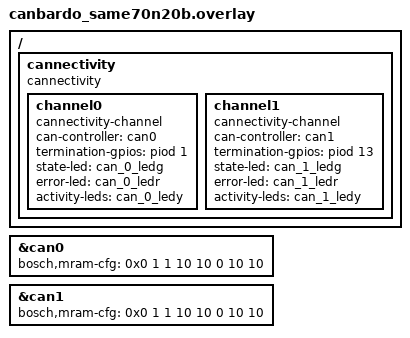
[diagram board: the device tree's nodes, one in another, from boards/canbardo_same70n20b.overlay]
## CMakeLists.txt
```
# Copyright (c) 2024 Henrik Brix Andersen <henrik@brixandersen.dk>
# SPDX-License-Identifier: Apache-2.0

cmake_minimum_required(VERSION 3.13.1)
find_package(Zephyr REQUIRED HINTS $ENV{ZEPHYR_BASE})

project(cannectivity LANGUAGES C)

if(CONFIG_CANNECTIVITY_USB_VID EQUAL 0x1209)
  if(CONFIG_CANNECTIVITY_USB_PID LESS_EQUAL 0x0010)
    message(WARNING
      "CONFIG_CANNECTIVITY_USB_PID is set to a generic pid.codes Test PID (${CONFIG_CANNECTIVITY_USB_PID}).
This PID is not unique and should not be used outside test environments."
      )
  endif()
endif()

if(CONFIG_CANNECTIVITY_DFU_BACKEND_APP)
  if(CONFIG_CANNECTIVITY_USB_DFU_VID EQUAL 0x1209)
    if(CONFIG_CANNECTIVITY_USB_DFU_PID LESS_EQUAL 0x0010)
      message(WARNING
        "CONFIG_CANNECTIVITY_USB_DFU_PID is set to a generic pid.codes Test PID (${CONFIG_CANNECTIVITY_USB_DFU_PID}).
This PID is not unique and should not be used outside test environments."
        )
    endif()
  endif()
endif()

target_sources(app PRIVATE
  src/main.c
  src/usb.c
)

target_sources_ifdef(CONFIG_CANNECTIVITY_LED app PRIVATE
  src/led.c
)

target_sources_ifdef(CONFIG_CANNECTIVITY_TIMESTAMP_COUNTER app PRIVATE
  src/timestamp-counter.c
)

target_sources_ifdef(CONFIG_CANNECTIVITY_TIMESTAMP_UPTIME app PRIVATE
  src/timestamp-uptime.c
)

target_sources_ifdef(CONFIG_CANNECTIVITY_TERMINATION_GPIO app PRIVATE
  src/termination.c
)

target_sources_ifdef(CONFIG_CANNECTIVITY_DFU_SUPPORT app PRIVATE
  src/dfu.c
)
```

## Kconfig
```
# Copyright (c) 2024-2025 Henrik Brix Andersen <henrik@brixandersen.dk>
# SPDX-License-Identifier: Apache-2.0

menu "CANnectivity"

module = CANNECTIVITY
module-str = CANnectivity
source "subsys/logging/Kconfig.template.log_config"

configdefault CAN_FD_MODE
	default y

config CANNECTIVITY_BOOT_BANNER
	bool "CANnectivity boot banner"
	default y if BOOT_BANNER
	select PRINTK
	help
	  Print the CANnectivity firmware version during boot up.

config CANNECTIVITY_USB_MANUFACTURER
	string "USB device manufacturer string"
	default "CANnectivity"
	help
	  CANnectivity USB device manufacturer string.

config CANNECTIVITY_USB_PRODUCT
	string "USB device product string"
	default "CANnectivity USB to CAN adapter"
	help
	  CANnectivity USB device product string.

config CANNECTIVITY_USB_VID
	hex "USB device Vendor ID (VID)"
	default 0x1209
	help
	  CANnectivity USB device Vendor ID (VID).

config CANNECTIVITY_USB_PID
	hex "USB device Product ID (PID)"
	default 0xca01
	help
	  CANnectivity USB device Product ID (PID).

config CANNECTIVITY_USB_SELF_POWERED
	bool "USB device is self-powered"
	default y
	help
	  CANnectivity USB device is self-powered.

config CANNECTIVITY_USB_MAX_POWER
	int "USB device maximum power"
	default 125
	range 0 250
	help
	  CANnectivity USB maximum current draw in milliampere (mA) divided by 2.
	  A value of 125 results in a maximum current draw value of 250 mA.

config CANNECTIVITY_MAX_CHANNELS
	int "Maximum number of supported channels"
	default 1 if !$(dt_compat_enabled,cannectivity-channel)
	default $(dt_compat_enabled_num,cannectivity-channel) if $(dt_compat_enabled,cannectivity-channel)
	range 1 256
	help
	  Maximum number of supported Geschwister Schneider USB/CAN (gs_usb) channels. Each channel
	  represents one CAN controller.

	  The Linux kernel driver supports up to 3 channels. Other drivers may support just one
	  channel.

if USB_DEVICE_STACK

configdefault USB_DEVICE_MANUFACTURER
	default CANNECTIVITY_USB_MANUFACTURER

configdefault USB_DEVICE_PRODUCT
	default CANNECTIVITY_USB_PRODUCT

configdefault USB_DEVICE_VID
	default CANNECTIVITY_USB_VID

configdefault USB_DEVICE_PID
	default CANNECTIVITY_USB_PID

configdefault USB_SELF_POWERED
	default CANNECTIVITY_USB_SELF_POWERED

configdefault USB_MAX_POWER
	default CANNECTIVITY_USB_MAX_POWER

configdefault USB_DEVICE_GS_USB_MAX_CHANNELS
	default CANNECTIVITY_MAX_CHANNELS

configdefault USB_DEVICE_BOS
	default y

configdefault USB_DEVICE_INITIALIZE_AT_BOOT
	default n

endif # USB_DEVICE_STACK

if USB_DEVICE_STACK_NEXT

configdefault USBD_GS_USB_MAX_CHANNELS
	default CANNECTIVITY_MAX_CHANNELS

endif # USB_DEVICE_STACK_NEXT

config CANNECTIVITY_LED
	bool "LED support"
	default y
	depends on $(dt_compat_any_has_prop,cannectivity-channel,state-led) || \
		   $(dt_compat_any_has_prop,cannectivity-channel,activity-leds) || \
		   ($(dt_alias_enabled,led0) && !$(dt_compat_enabled,cannectivity))
	select LED
	select SMF
	select SMF_ANCESTOR_SUPPORT
	select SMF_INITIAL_TRANSITION
	select POLL
	select USB_DEVICE_GS_USB_IDENTIFICATION if USB_DEVICE_GS_USB
	select USBD_GS_USB_IDENTIFICATION if USBD_GS_USB
	help
	  Enable support for CAN channel status/activity LEDs.

if CANNECTIVITY_LED

config CANNECTIVITY_LED_EVENT_MSGQ_SIZE
	int "LED event message queue size"
	default 10
	help
	  Number of per-channel LED events that can be queued for the finite-state machine.

endif # CANNECTIVITY_LED

config CANNECTIVITY_TIMESTAMP
	bool # hidden
	select USB_DEVICE_GS_USB_TIMESTAMP if USB_DEVICE_GS_USB
	select USBD_GS_USB_TIMESTAMP if USBD_GS_USB
	help
	  Enable support for hardware timestamps.

config CANNECTIVITY_TIMESTAMP_COUNTER
	bool "Hardware timestamp support (32-bit counter @ 1MHz)"
	default y
	depends on $(dt_nodelabel_has_prop,cannectivity,timestamp-counter)
	select COUNTER
	select CANNECTIVITY_TIMESTAMP
	help
	  Enable support for hardware timestamps. This requires a 32-bit counter instance running @
	  1MHz.

config CANNECTIVITY_TIMESTAMP_UPTIME
	bool "Hardware timestamp support (64-bit cycle counter)"
	default y
	depends on TIMER_HAS_64BIT_CYCLE_COUNTER
	depends on !CANNECTIVITY_TIMESTAMP_COUNTER
	select CANNECTIVITY_TIMESTAMP
	help
	  Enable support for hardware timestamps. This requires a 64-bit cycle counter.

config CANNECTIVITY_TERMINATION_GPIO
	bool "CAN bus termination resistor support"
	default y
	depends on $(dt_compat_any_has_prop,cannectivity-channel,termination-gpios)
	select USB_DEVICE_GS_USB_TERMINATION if USB_DEVICE_GS_USB
	select USBD_GS_USB_TERMINATION if USBD_GS_USB
	select GPIO
	help
	  Enable support for GPIO-controlled CAN bus termination resistors.

config CANNECTIVITY_TERMINATION_DEFAULT_ON
	bool "Enable CAN bus termination resistors on boot-up"
	default y
	depends on CANNECTIVITY_TERMINATION_GPIO
	help
	  Enable CAN bus termination resistors on boot-up.

menuconfig CANNECTIVITY_DFU_SUPPORT
	bool "Device Firmware Upgrade (DFU) support"
	default y if BOOTLOADER_MCUBOOT
	help
	  Enable Device Firmware Upgrade (DFU) support.

if CANNECTIVITY_DFU_SUPPORT

choice CANNECTIVITY_DFU_BACKEND
	bool "DFU backend"
	default CANNECTIVITY_DFU_BACKEND_NONE if !BOOTLOADER_MCUBOOT
	default CANNECTIVITY_DFU_BACKEND_MCUBOOT if BOOTLOADER_MCUBOOT && USB_DEVICE_STACK
	default CANNECTIVITY_DFU_BACKEND_MCUBOOT if BOOTLOADER_MCUBOOT && MCUBOOT_BOOTLOADER_MODE_SINGLE_APP
	default CANNECTIVITY_DFU_BACKEND_APP if BOOTLOADER_MCUBOOT && USB_DEVICE_STACK_NEXT

config CANNECTIVITY_DFU_BACKEND_NONE
	bool "No backend"
	help
	  Device Firmware Upgrade is handled by an on-chip ROM bootloader.

config CANNECTIVITY_DFU_BACKEND_MCUBOOT
	bool "MCUboot"
	depends on BOOTLOADER_MCUBOOT
	help
	  Device Firmware Upgrade is handled by rebooting into MCUboot, with the bootloader exposing
	  an USB DFU or serial recovery interface.

config CANNECTIVITY_DFU_BACKEND_APP
	bool "Application"
	depends on BOOTLOADER_MCUBOOT && !MCUBOOT_BOOTLOADER_MODE_SINGLE_APP && USB_DEVICE_STACK_NEXT
	help
	  Device Firmware Upgrade is handled by the CANnectivity firmware application. The upgrade
	  process is handled by MCUboot upon reboot.

endchoice

config CANNECTIVITY_DFU_REBOOT
	bool "Automatic reboot upon DFU download completion"
	depends on CANNECTIVITY_DFU_BACKEND_APP
	default y
	select REBOOT
	help
	  Automatically reboot device upon completion of a DFU download.

config CANNECTIVITY_DFU_REBOOT_DELAY
	int "Reboot delay"
	default 100
	range 0 60000
	depends on CANNECTIVITY_DFU_REBOOT
	help
	  Delay in milliseconds between completion of a DFU download and device reboot.

config CANNECTIVITY_USB_DFU_PRODUCT
	string "USB DFU device product string"
	default "CANnectivity USB to CAN adapter (DFU)"
	depends on CANNECTIVITY_DFU_BACKEND_APP
	help
	  CANnectivity USB device DFU product string.

config CANNECTIVITY_USB_DFU_VID
	hex "USB device DFU Vendor ID (VID)"
	default 0xffff if !CANNECTIVITY_DFU_BACKEND_APP
	default 0x1209 if CANNECTIVITY_DFU_BACKEND_APP
	help
	  CANnectivity USB device DFU Vendor ID (VID).

config CANNECTIVITY_USB_DFU_PID
	hex "USB device DFU Product ID (PID)"
	default 0xffff if !CANNECTIVITY_DFU_BACKEND_APP
	default 0xca02 if CANNECTIVITY_DFU_BACKEND_APP
	help
	  CANnectivity USB device DFU Product ID (PID).

if CANNECTIVITY_DFU_BACKEND_MCUBOOT || CANNECTIVITY_DFU_BACKEND_APP

config CANNECTIVITY_DFU_BUTTON
	bool "DFU button support"
	default y
	depends on $(dt_alias_enabled,mcuboot-button0)
	select GPIO
	select REBOOT if CANNECTIVITY_DFU_BACKEND_MCUBOOT
	help
	  Enable support for activating Device Firmware Upgrade (DFU) mode by holding the DFU button
	  (identified by the "mcuboot-button0" devicetree alias).

config CANNECTIVITY_DFU_BUTTON_HOLD_TIME
	int "DFU button hold time in seconds"
	depends on CANNECTIVITY_DFU_BUTTON
	range 1 60
	default 4
	help
	  Number of seconds the Device Firmware Upgrade (DFU) button must be held to activate DFU
	  mode.

config CANNECTIVITY_DFU_LED
	bool # hidden
	default y
	depends on $(dt_alias_enabled,mcuboot-led0)
	select LED
	help
	  Enable support for controlling the Device Firmware Upgrade (DFU) LED (identified by the
	  "mcuboot-led0" devicetree alias).

configdefault FLASH
	default y

configdefault STREAM_FLASH
	default y

configdefault FLASH_MAP
	default y

configdefault IMG_MANAGER
	default y

if CANNECTIVITY_DFU_BACKEND_APP

if ARM_MPU

configdefault MPU_ALLOW_FLASH_WRITE
	default y

endif # ARM_MPU

configdefault USBD_DFU
	default y

configdefault USBD_DFU_MANIFESTATION_TOLERANT
	default !CANNECTIVITY_DFU_REBOOT

configdefault USBD_DFU_FLASH
	default y

configdefault USBD_DFU_FLASH_SLOT0
	default n

configdefault USBD_DFU_FLASH_SLOT1
	default y

configdefault USBD_DFU_NUMOF_IMAGES
	default 1

configdefault IMG_ERASE_PROGRESSIVELY
	default y

endif # CANNECTIVITY_DFU_BACKEND_APP

endif # CANNECTIVITY_DFU_BACKEND_MCUBOOT || CANNECTIVITY_DFU_BACKEND_APP

config CANNECTIVITY_GENERATE_USB_DFU_IMAGE
	bool "Generate USB DFU image"
	select BUILD_OUTPUT_BIN
	default y
	help
	  Enabling this configuration allows automatic generation of an image with USB Device
	  Firmware Upgrade (DFU) suffix. This depends on the dfu-suffix utility from the dfu-util
	  software package.

config CANNECTIVITY_USB_DFU_SPEC_ID
	hex "USB DFU image Specification ID"
	default 0x0100
	depends on CANNECTIVITY_GENERATE_USB_DFU_IMAGE
	help
	  CANnectivity USB DFU image Specification ID.

endif # CANNECTIVITY_DFU_SUPPORT

endmenu

source "Kconfig.zephyr"
```

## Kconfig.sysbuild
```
# Copyright (c) 2024-2025 Henrik Brix Andersen <henrik@brixandersen.dk>
# SPDX-License-Identifier: Apache-2.0

config CANNECTIVITY_DFU_SUPPORT
	bool "CANnectivity DFU support via MCUboot"
	help
	  Enable support for CANnectivity USB Device Firmware Upgrade (DFU) mode using the MCUboot
	  bootloader.

if CANNECTIVITY_DFU_SUPPORT

choice BOOTLOADER
	default BOOTLOADER_MCUBOOT
endchoice # BOOTLOADER

choice BOOT_SIGNATURE_TYPE
	default BOOT_SIGNATURE_TYPE_NONE
endchoice # BOOT_SIGNATURE_TYPE

endif # CANNECTIVITY_DFU_SUPPORT

source "share/sysbuild/Kconfig"
```

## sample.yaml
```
# Copyright (c) 2024-2026 Henrik Brix Andersen <henrik@brixandersen.dk>
# SPDX-License-Identifier: Apache-2.0

sample:
  description: CANnectivity USB-to-CAN adapter firmware
  name: cannectivity
common:
  tags:
    - can
    - usb
  harness: console
  harness_config:
    type: one_line
    regex:
      - "CANnectivity firmware initialized with .*"
tests:
  app.cannectivity.legacy:
    depends_on:
      - can
      - usb_device
    extra_args:
      - FILE_SUFFIX=legacy
    integration_platforms:
      - canbardo
      - candlelight
      - candlelightfd
      - candlelightfd/stm32g0b1xx/dual
      - frdm_k64f
      - frdm_mcxn947/mcxn947/cpu0
      - lpcxpresso55s16
      - mks_canable_v20
      - nucleo_h723zg
      - ucan
      - usb2canfdv1
  app.cannectivity.legacy.sof:
    depends_on:
      - can
      - usb_device
    extra_args:
      - FILE_SUFFIX=legacy
    integration_platforms:
      - nucleo_h723zg
    extra_configs:
      - CONFIG_USB_DEVICE_GS_USB_TIMESTAMP_SOF=y
  app.cannectivity.legacy.release:
    depends_on:
      - can
      - usb_device
    extra_args:
      - FILE_SUFFIX=legacy_release
    integration_platforms:
      - canbardo
      - candlelight
      - candlelightfd
      - candlelightfd/stm32g0b1xx/dual
      - frdm_k64f
      - frdm_mcxn947/mcxn947/cpu0
      - lpcxpresso55s16
      - mks_canable_v20
      - nucleo_h723zg
      - ucan
      - usb2canfdv1
    build_only: true
  app.cannectivity:
    depends_on:
      - can
      - usbd
    integration_platforms:
      - canbardo
      - candlelightfd
      - candlelightfd/stm32g0b1xx/dual
      - frdm_k64f
      - frdm_mcxn947/mcxn947/cpu0
      - lpcxpresso55s16
      - nucleo_h723zg
      - usb2canfdv1
  app.cannectivity.sof:
    depends_on:
      - can
      - usbd
    integration_platforms:
      - lpcxpresso55s16
      - nucleo_h723zg
    extra_configs:
      - CONFIG_USBD_GS_USB_TIMESTAMP_SOF=y
  app.cannectivity.release:
    depends_on:
      - can
      - usbd
    extra_args:
      - FILE_SUFFIX=release
    integration_platforms:
      - canbardo
      - candlelight
      - candlelightfd
      - candlelightfd/stm32g0b1xx/dual
      - frdm_k64f
      - frdm_mcxn947/mcxn947/cpu0
      - lpcxpresso55s16
      - mks_canable_v20
      - nucleo_h723zg
      - ucan
      - usb2canfdv1
    build_only: true
  app.cannectivity.legacy.dfu:
    sysbuild: true
    depends_on:
      - can
      - usb_device
    platform_allow:
      - frdm_k64f
      - lpcxpresso55s16
      - canbardo
    extra_args:
      - FILE_SUFFIX=legacy
  app.cannectivity.dfu:
    sysbuild: true
    depends_on:
      - can
      - usbd
    platform_allow:
      - canbardo
      - frdm_k64f
      - frdm_mcxn947/mcxn947/cpu0
      - lpcxpresso55s16
```

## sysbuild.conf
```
# Copyright (c) 2024 Henrik Brix Andersen <henrik@brixandersen.dk>
# SPDX-License-Identifier: Apache-2.0

SB_CONFIG_CANNECTIVITY_DFU_SUPPORT=y
```

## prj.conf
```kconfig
CONFIG_USB_DEVICE_STACK_NEXT=y

# Logging configuration
CONFIG_LOG=y
CONFIG_UDC_DRIVER_LOG_LEVEL_WRN=y
CONFIG_USBD_LOG_LEVEL_WRN=y
CONFIG_USBD_GS_USB_LOG_LEVEL_DBG=y
CONFIG_CANNECTIVITY_LOG_LEVEL_DBG=y
```

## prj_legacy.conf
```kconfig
# This is using the deprecated USB device stack
CONFIG_DEPRECATION_TEST=y
CONFIG_USB_DEVICE_STACK=y

# Logging configuration
CONFIG_LOG=y
CONFIG_USB_DRIVER_LOG_LEVEL_ERR=y
CONFIG_USB_DEVICE_LOG_LEVEL_ERR=y
CONFIG_USB_DEVICE_GS_USB_LOG_LEVEL_DBG=y
CONFIG_CANNECTIVITY_LOG_LEVEL_DBG=y
```

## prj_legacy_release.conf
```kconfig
# This is using the deprecated USB device stack
CONFIG_DEPRECATION_TEST=y
CONFIG_USB_DEVICE_STACK=y

# Hardened configuration
CONFIG_BOOT_BANNER=n
CONFIG_BUILD_OUTPUT_STRIPPED=y
CONFIG_PRINTK=n
CONFIG_STACK_SENTINEL=y
CONFIG_OVERRIDE_FRAME_POINTER_DEFAULT=y

# Arm-specific hardened configuration
CONFIG_FAULT_DUMP=0
```

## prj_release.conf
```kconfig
CONFIG_USB_DEVICE_STACK_NEXT=y

# Hardened configuration
CONFIG_BOOT_BANNER=n
CONFIG_BUILD_OUTPUT_STRIPPED=y
CONFIG_PRINTK=n
CONFIG_STACK_SENTINEL=y
CONFIG_OVERRIDE_FRAME_POINTER_DEFAULT=y

# Arm-specific hardened configuration
CONFIG_FAULT_DUMP=0
```

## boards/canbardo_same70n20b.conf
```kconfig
# Copyright (c) 2026 Henrik Brix Andersen <henrik@brixandersen.dk>
# SPDX-License-Identifier: Apache-2.0

CONFIG_CANNECTIVITY_USB_SELF_POWERED=n
CONFIG_USBD_GS_USB_COMPATIBILITY_MODE=n
```

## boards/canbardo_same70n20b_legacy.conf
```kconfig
# Copyright (c) 2024-2025 Henrik Brix Andersen <henrik@brixandersen.dk>
# SPDX-License-Identifier: Apache-2.0

CONFIG_CANNECTIVITY_USB_SELF_POWERED=n
CONFIG_USB_DEVICE_GS_USB_COMPATIBILITY_MODE=n
```

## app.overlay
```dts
/*
 * Copyright (c) 2022-2025 Henrik Brix Andersen <henrik@brixandersen.dk>
 *
 * SPDX-License-Identifier: Apache-2.0
 */

/ {
	gs_usb0: gs_usb0 {
		compatible = "gs_usb";
		label = "gs_usb";
	};
};
```

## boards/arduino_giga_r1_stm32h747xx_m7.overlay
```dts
/*
 * Copyright (c) 2025 Felipe Neves
 *
 * SPDX-License-Identifier: Apache-2.0
 */

#include "../app.overlay"

/ {
	cannectivity: cannectivity {
		compatible = "cannectivity";
		timestamp-counter = <&counter0>;

		channel0 {
			compatible = "cannectivity-channel";
			can-controller = <&fdcan2>;
			state-led = <&blue_led>;
			activity-leds = <&green_led>;
		};
	};
};

&timers2 {
	st,prescaler = <239>;
	status = "okay";
	counter0: counter {
		status = "okay";
	};
};
```

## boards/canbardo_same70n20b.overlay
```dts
/*
 * Copyright (c) 2024-2025 Henrik Brix Andersen <henrik@brixandersen.dk>
 *
 * SPDX-License-Identifier: Apache-2.0
 */

#include <zephyr/dt-bindings/gpio/gpio.h>
#include "../app.overlay"

/ {
	cannectivity: cannectivity {
		compatible = "cannectivity";

		channel0 {
			compatible = "cannectivity-channel";
			can-controller = <&can0>;
			termination-gpios = <&piod 1 GPIO_ACTIVE_HIGH>;
			state-led = <&can_0_ledg>;
			error-led = <&can_0_ledr>;
			activity-leds = <&can_0_ledy>;
		};

		channel1 {
			compatible = "cannectivity-channel";
			can-controller = <&can1>;
			termination-gpios = <&piod 13 GPIO_ACTIVE_HIGH>;
			state-led = <&can_1_ledg>;
			error-led = <&can_1_ledr>;
			activity-leds = <&can_1_ledy>;
		};
	};
};

&can0 {
	bosch,mram-cfg = <0x0 1 1 10 10 0 10 10>;
};

&can1 {
	bosch,mram-cfg = <0x0 1 1 10 10 0 10 10>;
};
```

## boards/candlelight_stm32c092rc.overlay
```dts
/*
 * Copyright (c) 2024 Henrik Brix Andersen <henrik@brixandersen.dk>
 *
 * SPDX-License-Identifier: Apache-2.0
 */

#include <zephyr/dt-bindings/gpio/gpio.h>
#include "../app.overlay"

/ {
	cannectivity: cannectivity {
		compatible = "cannectivity";
		timestamp-counter = <&counter2>;

		channel0 {
			compatible = "cannectivity-channel";
			can-controller = <&can1>;
			activity-leds = <&led_rx &led_tx>;
		};
	};
};

&timers2 {
	status = "okay";
	st,prescaler = <47>;

	counter2: counter2 {
		compatible = "st,stm32-counter";
		status = "okay";
	};
};
```

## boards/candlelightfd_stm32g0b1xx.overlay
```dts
/*
 * Copyright (c) 2024-2025 Henrik Brix Andersen <henrik@brixandersen.dk>
 *
 * SPDX-License-Identifier: Apache-2.0
 */

#include <zephyr/dt-bindings/gpio/gpio.h>
#include "../app.overlay"

/ {
	cannectivity: cannectivity {
		compatible = "cannectivity";
		timestamp-counter = <&counter2>;

		channel0 {
			compatible = "cannectivity-channel";
			can-controller = <&fdcan1>;
			activity-leds = <&led_rx &led_tx>;
		};
	};
};

&timers2 {
	status = "okay";
	st,prescaler = <59>;

	counter2: counter2 {
		compatible = "st,stm32-counter";
		status = "okay";
	};
};
```

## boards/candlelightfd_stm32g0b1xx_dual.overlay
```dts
/*
 * Copyright (c) 2024-2025 Henrik Brix Andersen <henrik@brixandersen.dk>
 *
 * SPDX-License-Identifier: Apache-2.0
 */

#include <zephyr/dt-bindings/gpio/gpio.h>
#include "../app.overlay"

/ {
	cannectivity: cannectivity {
		compatible = "cannectivity";
		timestamp-counter = <&counter2>;

		channel0 {
			compatible = "cannectivity-channel";
			can-controller = <&fdcan1>;
			/* Use RX LED for channel 0 state + activity */
			state-led = <&led_rx>;
		};

		channel1 {
			compatible = "cannectivity-channel";
			can-controller = <&fdcan2>;
			/* Use TX LED for channel 0 state + activity */
			state-led = <&led_tx>;
		};
	};
};

&timers2 {
	status = "okay";
	st,prescaler = <59>;

	counter2: counter2 {
		compatible = "st,stm32-counter";
		status = "okay";
	};
};
```

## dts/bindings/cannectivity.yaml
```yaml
# Copyright (c) 2024 Henrik Brix Andersen <henrik@brixandersen.dk>
# SPDX-License-Identifier: Apache-2.0

description: |
  CANnectivity hardware configuration

  Example:
    cannectivity: cannectivity {
      compatible = "cannectivity";
      timestamp-counter = <&counter0>;

      channel {
        compatible = "cannectivity-channel";
        can-controller = <&can0>;
        termination-gpios = <&gpio0 6 GPIO_ACTIVE_HIGH>;
        state-led = <&ch0_state_led>;
        error-led = <&ch0_error_led>;
        activity-leds = <&ch0_activity_led>;
      };

      channel {
        compatible = "cannectivity-channel";
        can-controller = <&can1>;
        termination-gpios = <&gpio0 9 GPIO_ACTIVE_HIGH>;
        state-led = <&ch1_state_led>;
        error-led = <&ch1_error_led>;
        activity-leds = <&ch1_activity_led>;
      };
    };

compatible: "cannectivity"

include: base.yaml

properties:
  timestamp-counter:
    type: phandle
    description: |
      Phandle to 32-bit counter node running @ 1MHz. This counter is used for hardware timestamping
      of received and transmitted CAN frames.

child-binding:
  description: |
    CANnectivity CAN channel configuration. Channels are indexed in the order they appear in the
    final devicetree.

  compatible: "cannectivity-channel"

  properties:
    can-controller:
      type: phandle
      required: true
      description: |
        Phandle to the CAN controller node for this CAN channel.

    termination-gpios:
      type: phandle-array
      description: |
        GPIO to use to enable/disable the CAN channel termination resistor. This GPIO is driven
        active when the CAN termination is enabled and inactive when the CAN termination is
        disabled.

    state-led:
      type: phandle
      description: |
        Phandle for the CAN channel state LED.

    error-led:
      type: phandle
      description: |
        Phandle for the CAN channel error LED.

    activity-leds:
      type: phandles
      description: |
        Phandle(s) for the CAN channel activity LED(s).

        If two LED phandles are specified, the LED phandle at index 0 will be used for indicating RX
        activity, and the LED phandle at index 1 will be used for indicating TX activity.
```

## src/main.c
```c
/*
 * Copyright (c) 2024 Henrik Brix Andersen <henrik@brixandersen.dk>
 *
 * SPDX-License-Identifier: Apache-2.0
 */

#include <zephyr/device.h>
#include <zephyr/devicetree.h>
#include <zephyr/logging/log.h>
#include <zephyr/usb/usbd.h>

#include <cannectivity/usb/class/gs_usb.h>

#include "cannectivity.h"
#include "zephyr/app_version.h"

LOG_MODULE_REGISTER(main, CONFIG_CANNECTIVITY_LOG_LEVEL);

#ifdef CONFIG_CANNECTIVITY_BOOT_BANNER
#if defined(APP_BUILD_VERSION) && !IS_EMPTY(APP_BUILD_VERSION)
#define CANNECTIVITY_BANNER_VERSION STRINGIFY(APP_BUILD_VERSION)
#else
#define CANNECTIVITY_BANNER_VERSION APP_VERSION_STRING
#endif
#endif /* CONFIG_CANNECTIVITY_BOOT_BANNER */

#define CHANNEL_CAN_CONTROLLER_DT_GET(node_id) DEVICE_DT_GET(DT_PHANDLE(node_id, can_controller))

static const struct gs_usb_ops gs_usb_ops = {
#ifdef CONFIG_CANNECTIVITY_TIMESTAMP
	.timestamp = cannectivity_timestamp_get,
#endif
#ifdef CONFIG_CANNECTIVITY_LED
	.event = cannectivity_led_event,
#endif
#ifdef CONFIG_CANNECTIVITY_TERMINATION_GPIO
	.set_termination = cannectivity_set_termination,
	.get_termination = cannectivity_get_termination,
#endif
};

int main(void)
{
	const struct device *gs_usb = DEVICE_DT_GET(DT_NODELABEL(gs_usb0));
	const struct device *channels[] = {
#if CANNECTIVITY_DT_HAS_CHANNEL
		CANNECTIVITY_DT_FOREACH_CHANNEL_SEP(CHANNEL_CAN_CONTROLLER_DT_GET, (,))
#else /* CANNECTIVITY_DT_HAS_CHANNEL */
		DEVICE_DT_GET(DT_CHOSEN(zephyr_canbus))
#endif /* !CANNECTIVITY_DT_HAS_CHANNEL */
	};
	int err;

#ifdef CONFIG_CANNECTIVITY_BOOT_BANNER
	printk("*** CANnectivity firmware " CANNECTIVITY_BANNER_VERSION " ***\n");
#endif /* CONFIG_CANNECTIVITY_BOOT_BANNER */

	if (!device_is_ready(gs_usb)) {
		LOG_ERR("gs_usb USB device not ready");
		return 0;
	}

	if (IS_ENABLED(CONFIG_CANNECTIVITY_LED)) {
		err = cannectivity_led_init();
		if (err != 0) {
			return 0;
		}
	}

	if (IS_ENABLED(CONFIG_CANNECTIVITY_TERMINATION_GPIO)) {
		err = cannectivity_termination_init();
		if (err != 0) {
			return 0;
		}
	}

	if (IS_ENABLED(CONFIG_CANNECTIVITY_TIMESTAMP)) {
		err = cannectivity_timestamp_init();
		if (err != 0) {
			return 0;
		}
	}

	err = gs_usb_register(gs_usb, channels, ARRAY_SIZE(channels), &gs_usb_ops, NULL);
	if (err != 0U) {
		LOG_ERR("failed to register gs_usb (err %d)", err);
		return 0;
	}

	err = cannectivity_usb_init();
	if (err) {
		LOG_ERR("failed to enable USB device");
		return err;
	}

	if (IS_ENABLED(CONFIG_CANNECTIVITY_DFU_SUPPORT)) {
		err = cannectivity_dfu_init();
		if (err) {
			LOG_ERR("failed to initialize DFU");
			return err;
		}
	}

	LOG_INF("CANnectivity firmware initialized with %u channel%s", ARRAY_SIZE(channels),
		ARRAY_SIZE(channels) > 1 ? "s" : "");
}
```

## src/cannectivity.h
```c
/*
 * Copyright (c) 2024 Henrik Brix Andersen <henrik@brixandersen.dk>
 *
 * SPDX-License-Identifier: Apache-2.0
 */

#ifndef CANNECTIVITY_APP_CANNECTIVITY_H_
#define CANNECTIVITY_APP_CANNECTIVITY_H_

#include <zephyr/device.h>
#include <zephyr/devicetree.h>
#include <cannectivity/usb/class/gs_usb.h>

/**
 * @brief The CANnectivity devicetree hardware configuration node identifier
 */
#define CANNECTIVITY_DT_NODE_ID DT_NODELABEL(cannectivity)

/**
 * @brief True if one or more CANnectivity channels are present in the devicetree, false otherwise
 */
#define CANNECTIVITY_DT_HAS_CHANNEL DT_HAS_COMPAT_STATUS_OKAY(cannectivity_channel)

/**
 * @brief Invokes @p fn for each CANnectivity devicetree channel node with a separator
 *
 * The macro @p fn must take one parameter, which will be the node identifier of a CANnectivity
 * channel node.
 *
 * @param fn The macro to invoke.
 * @param sep Separator (e.g. comma or semicolon). Must be in parentheses;
 *            this is required to enable providing a comma as separator.
 */
#define CANNECTIVITY_DT_FOREACH_CHANNEL_SEP(fn, sep)                                               \
	DT_FOREACH_CHILD_STATUS_OKAY_SEP(CANNECTIVITY_DT_NODE_ID, fn, sep)

/**
 * @brief CANnectivity CAN channel LED event callback
 *
 * @param dev Pointer to the device structure for the driver instance.
 * @param ch CAN channel number.
 * @param event Channel event.
 * @param user_data User data provided when registering the callback.
 * @return 0 on success, negative error number otherwise.
 */
int cannectivity_led_event(const struct device *dev, uint16_t ch, enum gs_usb_event event,
			   void *user_data);

/**
 * @brief CANnectivity LED initialization function
 *
 * @return 0 on success, negative error number otherwise.
 */
int cannectivity_led_init(void);

/**
 * @brief CANnectivity CAN channel set CAN bus termination callback
 *
 * @param dev Pointer to the device structure for the driver instance.
 * @param ch CAN channel number.
 * @param terminate True if the channel termination is active, false otherwise.
 * @param user_data User data provided when registering the callback.
 * @return 0 on success, negative error number otherwise.
 */
int cannectivity_set_termination(const struct device *dev, uint16_t ch, bool terminate,
				 void *user_data);

/**
 * @brief CANnectivity CAN channel get CAN bus termination callback
 *
 * @param dev Pointer to the device structure for the driver instance.
 * @param ch CAN channel number.
 * @param[out] terminated True if the channel termination is active, false otherwise.
 * @param user_data User data provided when registering the callback.
 * @return 0 on success, negative error number otherwise.
 */
int cannectivity_get_termination(const struct device *dev, uint16_t ch, bool *terminated,
				 void *user_data);

/**
 * @brief CANnectivity CAN bus termination initialization function
 *
 * @return 0 on success, negative error number otherwise.
 */
int cannectivity_termination_init(void);

/**
 * @brief CANnectivity get hardware timestamp callback
 *
 * @param dev Pointer to the device structure for the driver instance.
 * @param[out] timestamp Current timestamp value.
 * @param user_data User data provided when registering the callback.
 * @return 0 on success, negative error number otherwise.
 */
int cannectivity_timestamp_get(const struct device *dev, uint32_t *timestamp, void *user_data);

/**
 * @brief CANnectivity hardware timestamp initialization function
 *
 * @return 0 on success, negative error number otherwise.
 */
int cannectivity_timestamp_init(void);

#ifdef CONFIG_CANNECTIVITY_DFU_BACKEND_APP
/**
 * @brief Switch CANnectivity to USB DFU mode
 */
void cannectivity_usb_switch_to_dfu_mode(void);
#endif /* CONFIG_CANNECTIVITY_DFU_BACKEND_APP */

/**
 * @brief CANnectivity USB device initialization function
 *
 * @return 0 on success, negative error number otherwise.
 */
int cannectivity_usb_init(void);

#ifdef CONFIG_CANNECTIVITY_DFU_LED
/**
 * @brief Turn on DFU LED
 *
 * @return 0 on success, negative error number otherwise.
 */
int cannectivity_dfu_led_on(void);
#endif /* CONFIG_CANNECTIVITY_DFU_LED */

/**
 * @brief CANnectivity USB DFU initialization function
 *
 * @return 0 on success, negative error number otherwise.
 */
int cannectivity_dfu_init(void);

#endif /* CANNECTIVITY_APP_CANNECTIVITY_H_ */
```

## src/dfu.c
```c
/*
 * Copyright (c) 2024 Henrik Brix Andersen <henrik@brixandersen.dk>
 *
 * SPDX-License-Identifier: Apache-2.0
 */

#include <zephyr/sys_clock.h>
#include <zephyr/dfu/mcuboot.h>
#include <zephyr/drivers/gpio.h>
#include <zephyr/drivers/led.h>
#include <zephyr/kernel.h>
#include <zephyr/logging/log.h>
#include <zephyr/sys/reboot.h>

#include "cannectivity.h"

LOG_MODULE_REGISTER(dfu, CONFIG_CANNECTIVITY_LOG_LEVEL);

/* DFU button poll timing */
#define DFU_BUTTON_POLL_HZ 5
#define DFU_BUTTON_POLL_INTERVAL_MS (MSEC_PER_SEC / DFU_BUTTON_POLL_HZ)
#define DFU_BUTTON_POLL_TOTAL (CONFIG_CANNECTIVITY_DFU_BUTTON_HOLD_TIME * DFU_BUTTON_POLL_HZ)

/* DFU button and LED devicetree nodes */
#define DFU_LED_NODE DT_ALIAS(mcuboot_led0)
#define DFU_BUTTON_NODE DT_ALIAS(mcuboot_button0)

#ifdef CONFIG_CANNECTIVITY_DFU_LED
struct led_dt_spec dfu_led = LED_DT_SPEC_GET(DFU_LED_NODE);
#endif /* CONFIG_CANNECTIVITY_DFU_LED */

#ifdef CONFIG_CANNECTIVITY_DFU_BUTTON
struct gpio_dt_spec dfu_button = GPIO_DT_SPEC_GET(DFU_BUTTON_NODE, gpios);
static struct gpio_callback dfu_button_cb;
static struct k_work_delayable dfu_button_work;
static struct k_sem dfu_button_sem;

static void dfu_button_poll(struct k_work *work)
{
	struct k_work_delayable *dwork = k_work_delayable_from_work(work);
	int err;

	err = gpio_pin_get_dt(&dfu_button);
	if (err < 0) {
		LOG_ERR("failed to get DFU button state (err %d)", err);
		goto done;
	}

	if (err > 0) {
#ifdef CONFIG_CANNECTIVITY_DFU_LED
		if (k_sem_count_get(&dfu_button_sem) % 2U == 0U) {
			err = led_on_dt(&dfu_led);
		} else {
			err = led_off_dt(&dfu_led);
		}
		if (err != 0) {
			LOG_ERR("failed to toggle DFU LED (err %d)", err);
			goto done;
		}
#endif /* CONFIG_CANNECTIVITY_DFU_LED */

		k_sem_give(&dfu_button_sem);
		if (k_sem_count_get(&dfu_button_sem) >= DFU_BUTTON_POLL_TOTAL) {
#ifdef CONFIG_CANNECTIVITY_DFU_BACKEND_APP
			err = gpio_remove_callback_dt(&dfu_button, &dfu_button_cb);
			if (err != 0) {
				LOG_ERR("failed to remove DFU button callback (err %d)", err);
				goto done;
			}

#ifdef CONFIG_CANNECTIVITY_DFU_LED
			err = led_off_dt(&dfu_led);
			if (err != 0) {
				LOG_ERR("failed to turn off DFU LED (err %d)", err);
				goto done;
			}
#endif /* CONFIG_CANNECTIVITY_DFU_LED */

			cannectivity_usb_switch_to_dfu_mode();
			return;
#else  /* CONFIG_CANNECTIVITY_DFU_BACKEND_APP */
			LOG_INF("rebooting");
			sys_reboot(SYS_REBOOT_COLD);
#endif /* !CONFIG_CANNECTIVITY_DFU_BACKEND_APP */
		}

		k_work_reschedule(dwork, K_MSEC(DFU_BUTTON_POLL_INTERVAL_MS));
		return;
	}

done:
#ifdef CONFIG_CANNECTIVITY_DFU_LED
	err = led_off_dt(&dfu_led);
	if (err != 0) {
		LOG_ERR("failed to turn off DFU LED (err %d)", err);
		return;
	}
#endif /* CONFIG_CANNECTIVITY_DFU_LED */
}

static void dfu_button_interrupt(const struct device *port, struct gpio_callback *cb,
				 gpio_port_pins_t pins)
{
	ARG_UNUSED(port);
	ARG_UNUSED(cb);
	ARG_UNUSED(pins);

	k_sem_reset(&dfu_button_sem);
	k_work_reschedule(&dfu_button_work, K_NO_WAIT);
}

static int dfu_button_init(void)
{
	int err;

	err = k_sem_init(&dfu_button_sem, 0, K_SEM_MAX_LIMIT);
	if (err != 0) {
		LOG_ERR("failed to initialize DFU button semaphore (err %d)", err);
		return err;
	}

	if (!gpio_is_ready_dt(&dfu_button)) {
		LOG_ERR("DFU button device not ready");
		return -ENODEV;
	}

	err = gpio_pin_configure_dt(&dfu_button, GPIO_INPUT);
	if (err != 0) {
		LOG_ERR("failed to configure DFU button (err %d)", err);
		return err;
	}

	err = gpio_pin_interrupt_configure_dt(&dfu_button, GPIO_INT_EDGE_TO_ACTIVE);
	if (err != 0) {
		LOG_ERR("failed to configure DFU button interrupt (err %d)", err);
		return err;
	}

	k_work_init_delayable(&dfu_button_work, dfu_button_poll);

	gpio_init_callback(&dfu_button_cb, dfu_button_interrupt, BIT(dfu_button.pin));
	err = gpio_add_callback_dt(&dfu_button, &dfu_button_cb);
	if (err != 0) {
		LOG_ERR("failed to add DFU button callback (err %d)", err);
		return err;
	}

	return 0;
}
#endif /* CONFIG_CANNECTIVITY_DFU_BUTTON */

#ifdef CONFIG_CANNECTIVITY_DFU_LED
int cannectivity_dfu_led_on(void)
{
	return led_on_dt(&dfu_led);
}

static int dfu_led_init(void)
{
	if (!led_is_ready_dt(&dfu_led)) {
		LOG_ERR("DFU LED device not ready");
		return -ENODEV;
	}

	return 0;
}
#endif /* CONFIG_CANNECTIVITY_DFU_LED */

int cannectivity_dfu_init(void)
{
	int err = 0;

#if defined(CONFIG_CANNECTIVITY_DFU_BACKEND_MCUBOOT) || defined(CONFIG_CANNECTIVITY_DFU_BACKEND_APP)
	/*
	 * Confirm updated image if running under MCUboot booloader. This could be done on
	 * successful USB enumeration instead, but that could cause unwanted image reverts on
	 * e.g. self-powered development boards.
	 */
	if (!boot_is_img_confirmed()) {
		err = boot_write_img_confirmed();
		if (err != 0) {
			LOG_ERR("failed to confirm image (err %d)", err);
			return err;
		}

		LOG_INF("image confirmed");
	}
#endif /* CONFIG_CANNECTIVITY_DFU_BACKEND_MCUBOOT || CONFIG_CANNECTIVITY_DFU_BACKEND_APP */

#ifdef CONFIG_CANNECTIVITY_DFU_LED
	err = dfu_led_init();
	if (err != 0) {
		return err;
	}
#endif /* CONFIG_CANNECTIVITY_DFU_LED */

#ifdef CONFIG_CANNECTIVITY_DFU_BUTTON
	err = dfu_button_init();
	if (err != 0) {
		return err;
	}
#endif /* CONFIG_CANNECTIVITY_DFU_BUTTON */

	return err;
}
```

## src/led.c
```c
/*
 * Copyright (c) 2024 Henrik Brix Andersen <henrik@brixandersen.dk>
 *
 * SPDX-License-Identifier: Apache-2.0
 */

#include <zephyr/device.h>
#include <zephyr/drivers/led.h>
#include <zephyr/kernel.h>
#include <zephyr/logging/log.h>
#include <zephyr/smf.h>
#include <zephyr/sys_clock.h>

#include "cannectivity.h"

LOG_MODULE_REGISTER(led, CONFIG_CANNECTIVITY_LOG_LEVEL);

/* LED ticks */
#define LED_TICK_MS        50U
#define LED_TICKS_ACTIVITY 2U
#define LED_TICKS_IDENTIFY 20U

/* LED finite-state machine states */
enum led_state {
	LED_STATE_NORMAL,
	LED_STATE_NORMAL_STARTED,
	LED_STATE_NORMAL_STOPPED,
	LED_STATE_IDENTIFY,
};

/* LED finite-state machine events */
enum led_event {
	LED_EVENT_TICK,
	LED_EVENT_CHANNEL_IDENTIFY_ON,
	LED_EVENT_CHANNEL_IDENTIFY_OFF,
	LED_EVENT_CHANNEL_STARTED,
	LED_EVENT_CHANNEL_STOPPED,
	LED_EVENT_CHANNEL_ACTIVITY_RX,
	LED_EVENT_CHANNEL_ACTIVITY_TX,
	LED_EVENT_CHANNEL_ERROR_ON,
	LED_EVENT_CHANNEL_ERROR_OFF,
};

/* Activity types */
enum led_activity {
	LED_ACTIVITY_RX = 0U,
	LED_ACTIVITY_TX,
	LED_ACTIVITY_COUNT,
};

/* LED finite-state machine event data type */
typedef uint32_t led_event_t;

/* LED finite-state machine per-channel context */
struct led_ctx {
	struct smf_ctx ctx;
	char eventq_buf[sizeof(led_event_t) * CONFIG_CANNECTIVITY_LED_EVENT_MSGQ_SIZE];
	struct k_msgq eventq;
	struct k_work_poll eventq_work;
	struct k_poll_event eventq_poll_events[1];
	led_event_t event;
	uint16_t ch;
	bool started;
	bool error;
	struct led_dt_spec state_led;
	struct led_dt_spec error_led;
	int identify_ticks;
	k_timepoint_t activity[LED_ACTIVITY_COUNT];
	int ticks[LED_ACTIVITY_COUNT];
	struct led_dt_spec activity_led[LED_ACTIVITY_COUNT];
};

/* Devicetree accessor macros */
#define CHANNEL_LED_DT_SPEC_GET(node_id)                                                           \
	{                                                                                          \
		.state_led = LED_DT_SPEC_GET_OR(DT_PHANDLE(node_id, state_led), {0}),              \
		.error_led = LED_DT_SPEC_GET_OR(DT_PHANDLE(node_id, error_led), {0}),              \
		.activity_led[0] = LED_DT_SPEC_GET_OR(DT_PHANDLE_BY_IDX(node_id, activity_leds, 0),\
						      {0}),                                        \
		.activity_led[1] = LED_DT_SPEC_GET_OR(DT_PHANDLE_BY_IDX(node_id, activity_leds, 1),\
						      {0}),                                        \
	}

#define CHANNEL_LED0_DT_SPEC_GET()                                                                 \
	{                                                                                          \
		.state_led = LED_DT_SPEC_GET(DT_ALIAS(led0)),                                      \
	}

/* Array of LED finite-state machine channel contexts */
struct led_ctx led_channel_ctx[] = {
#if CANNECTIVITY_DT_HAS_CHANNEL
	CANNECTIVITY_DT_FOREACH_CHANNEL_SEP(CHANNEL_LED_DT_SPEC_GET, (,))
#else /* CANNECTIVITY_DT_HAS_CHANNEL */
	CHANNEL_LED0_DT_SPEC_GET()
#endif /* !CANNECTIVITY_DT_HAS_CHANNEL */
};

/* Helper macros */
#define LED_CTX_HAS_STATE_LED(_led_ctx)                                                            \
	(_led_ctx->state_led.dev != NULL)
#define LED_CTX_HAS_ERROR_LED(_led_ctx)                                                            \
	(_led_ctx->error_led.dev != NULL)
#define LED_CTX_HAS_ACTIVITY_LED(_led_ctx)                                                         \
	(_led_ctx->activity_led[LED_ACTIVITY_RX].dev != NULL)
#define LED_CTX_HAS_DUAL_ACTIVITY_LEDS(_led_ctx)                                                   \
	(_led_ctx->activity_led[LED_ACTIVITY_TX].dev != NULL)

/* Forward declarations */
static const struct smf_state led_states[];
static void led_tick(struct k_timer *timer);

/* Variables */
static K_TIMER_DEFINE(led_tick_timer, led_tick, NULL);

static int led_event_enqueue(uint16_t ch, led_event_t event)
{
	struct led_ctx *lctx;
	int err;

	if (ch >= ARRAY_SIZE(led_channel_ctx)) {
		LOG_ERR("event %u for non-existing channel %u", event, ch);
		return -EINVAL;
	}

	lctx = &led_channel_ctx[ch];
	err = k_msgq_put(&lctx->eventq, &event, K_NO_WAIT);
	if (err != 0) {
		LOG_ERR("failed to enqueue event %u for channel %u (err %d)", event, ch, err);
	}

	return 0;
}

static void led_indicate_state(struct led_ctx *lctx, bool state)
{
	int err;

	if (LED_CTX_HAS_STATE_LED(lctx)) {
		if (state) {
			err = led_on_dt(&lctx->state_led);
		} else {
			err = led_off_dt(&lctx->state_led);
		}
		if (err != 0) {
			LOG_ERR("failed to turn %s channel %u state LED (err %d)",
				state ? "on" : "off", lctx->ch, err);
		}
	}
}

static void led_indicate_error(struct led_ctx *lctx, bool error)
{
	int err;

	if (LED_CTX_HAS_ERROR_LED(lctx)) {
		if (error) {
			err = led_on_dt(&lctx->error_led);
		} else {
			err = led_off_dt(&lctx->error_led);
		}
		if (err != 0) {
			LOG_ERR("failed to turn %s channel %u error LED (err %d)",
				error ? "on" : "off", lctx->ch, err);
		}
	}
}

static void led_indicate_activity(struct led_ctx *lctx, enum led_activity type, bool activity)
{
	struct led_dt_spec *led = NULL;
	int value = activity;
	int err;

	switch (type) {
	case LED_ACTIVITY_RX:
		if (LED_CTX_HAS_ACTIVITY_LED(lctx)) {
			led = &lctx->activity_led[LED_ACTIVITY_RX];
		}
		break;

	case LED_ACTIVITY_TX:
		if (LED_CTX_HAS_DUAL_ACTIVITY_LEDS(lctx)) {
			led = &lctx->activity_led[LED_ACTIVITY_TX];
		} else if (LED_CTX_HAS_ACTIVITY_LED(lctx)) {
			led = &lctx->activity_led[LED_ACTIVITY_RX];
		}

		break;

	default:
		__ASSERT_NO_MSG(false);
		break;
	}

	if (led == NULL && lctx->started && LED_CTX_HAS_STATE_LED(lctx)) {
		led = &lctx->state_led;
		value = !value;
	}

	if (led != NULL) {
		if (value) {
			err = led_on_dt(led);
		} else {
			err = led_off_dt(led);
		}
		if (err != 0) {
			LOG_ERR("failed to turn %s channel %u activity LED (err %d)",
				value ? "on" : "off", lctx->ch, err);
		}
	}
}

static enum smf_state_result led_state_normal_run(void *obj)
{
	struct led_ctx *lctx = obj;

	switch (lctx->event) {
	case LED_EVENT_CHANNEL_IDENTIFY_ON:
		smf_set_state(SMF_CTX(lctx), &led_states[LED_STATE_IDENTIFY]);
		break;
	default:
		return SMF_EVENT_PROPAGATE;
	}

	return SMF_EVENT_HANDLED;
}

static void led_state_normal_stopped_entry(void *obj)
{
	struct led_ctx *lctx = obj;

	if (lctx->started) {
		smf_set_state(SMF_CTX(obj), &led_states[LED_STATE_NORMAL_STARTED]);
		return;
	}

	led_indicate_state(lctx, false);
	led_indicate_error(lctx, false);
	led_indicate_activity(lctx, LED_ACTIVITY_RX, false);
	led_indicate_activity(lctx, LED_ACTIVITY_TX, false);
}

static enum smf_state_result led_state_normal_stopped_run(void *obj)
{
	struct led_ctx *lctx = obj;

	switch (lctx->event) {
	case LED_EVENT_CHANNEL_STARTED:
		lctx->started = true;
		smf_set_state(SMF_CTX(lctx), &led_states[LED_STATE_NORMAL_STARTED]);
		break;
	default:
		return SMF_EVENT_PROPAGATE;
	}

	return SMF_EVENT_HANDLED;
}

static void led_state_normal_started_entry(void *obj)
{
	struct led_ctx *lctx = obj;

	led_indicate_state(lctx, true);
	led_indicate_error(lctx, lctx->error);
	led_indicate_activity(lctx, LED_ACTIVITY_RX, false);
	led_indicate_activity(lctx, LED_ACTIVITY_TX, false);
}

static enum smf_state_result led_state_normal_started_run(void *obj)
{
	struct led_ctx *lctx = obj;
	int i;

	switch (lctx->event) {
	case LED_EVENT_TICK:
		for (i = 0; i < ARRAY_SIZE(lctx->ticks); i++) {
			if (lctx->ticks[i] != 0U) {
				lctx->ticks[i]--;
				if (lctx->ticks[i] == (LED_TICKS_ACTIVITY / 2U)) {
					led_indicate_activity(lctx, i, true);
				} else if (lctx->ticks[i] == 0U) {
					led_indicate_activity(lctx, i, false);
				}
			}
		}
		break;
	case LED_EVENT_CHANNEL_STOPPED:
		lctx->started = false;
		smf_set_state(SMF_CTX(lctx), &led_states[LED_STATE_NORMAL_STOPPED]);
		break;
	case LED_EVENT_CHANNEL_ACTIVITY_TX:
		lctx->ticks[LED_ACTIVITY_TX] = LED_TICKS_ACTIVITY;
		break;
	case LED_EVENT_CHANNEL_ACTIVITY_RX:
		lctx->ticks[LED_ACTIVITY_RX] = LED_TICKS_ACTIVITY;
		break;
	case LED_EVENT_CHANNEL_ERROR_ON:
		lctx->error = true;
		led_indicate_error(lctx, true);
		break;
	case LED_EVENT_CHANNEL_ERROR_OFF:
		lctx->error = false;
		led_indicate_error(lctx, false);
		break;
	default:
		return SMF_EVENT_PROPAGATE;
	}

	return SMF_EVENT_HANDLED;
}

static void led_state_identify_entry(void *obj)
{
	struct led_ctx *lctx = obj;

	lctx->identify_ticks = LED_TICKS_IDENTIFY;

	led_indicate_state(lctx, true);
	led_indicate_error(lctx, true);
	led_indicate_activity(lctx, LED_ACTIVITY_RX, true);
	led_indicate_activity(lctx, LED_ACTIVITY_TX, true);
}

static enum smf_state_result led_state_identify_run(void *obj)
{
	struct led_ctx *lctx = obj;
	struct led_dt_spec *leds[4];
	int err;
	int i;

	switch (lctx->event) {
	case LED_EVENT_TICK:
		leds[0] = &lctx->state_led;
		leds[1] = &lctx->error_led;
		leds[2] = &lctx->activity_led[LED_ACTIVITY_RX];
		leds[3] = &lctx->activity_led[LED_ACTIVITY_TX];

		lctx->identify_ticks--;

		if (lctx->identify_ticks == LED_TICKS_IDENTIFY / 2U) {
			for (i = 0; i < ARRAY_SIZE(leds); i++) {
				if (leds[i]->dev != NULL) {
					err = led_off_dt(leds[i]);
					if (err != 0) {
						LOG_ERR("failed to turn channel %u LED %d off"
							"(err %d)", lctx->ch, i, err);
					}
				}
			}
		} else if (lctx->identify_ticks == 0U) {
			for (i = 0; i < ARRAY_SIZE(leds); i++) {
				if (leds[i]->dev != NULL) {
					err = led_on_dt(leds[i]);
					if (err != 0) {
						LOG_ERR("failed to turn channel %u LED %d on "
							"(err %d)", lctx->ch, i, err);
					}
				}
			}

			lctx->identify_ticks = LED_TICKS_IDENTIFY;
		}
		break;
	case LED_EVENT_CHANNEL_STARTED:
		lctx->started = true;
		break;
	case LED_EVENT_CHANNEL_STOPPED:
		lctx->started = false;
		break;
	case LED_EVENT_CHANNEL_IDENTIFY_OFF:
		smf_set_state(SMF_CTX(lctx), &led_states[LED_STATE_NORMAL]);
		break;
	case LED_EVENT_CHANNEL_ERROR_ON:
		lctx->error = true;
		break;
	case LED_EVENT_CHANNEL_ERROR_OFF:
		lctx->error = false;
		break;
	default:
		return SMF_EVENT_PROPAGATE;
	}

	return SMF_EVENT_HANDLED;
}

/* clang-format off */
static const struct smf_state led_states[] = {
	[LED_STATE_NORMAL] = SMF_CREATE_STATE(NULL,
					      led_state_normal_run,
					      NULL,
					      NULL,
					      &led_states[LED_STATE_NORMAL_STOPPED]),
	[LED_STATE_NORMAL_STOPPED] = SMF_CREATE_STATE(led_state_normal_stopped_entry,
						      led_state_normal_stopped_run,
						      NULL,
						      &led_states[LED_STATE_NORMAL],
						      NULL),
	[LED_STATE_NORMAL_STARTED] = SMF_CREATE_STATE(led_state_normal_started_entry,
						      led_state_normal_started_run,
						      NULL,
						      &led_states[LED_STATE_NORMAL],
						      NULL),
	[LED_STATE_IDENTIFY] = SMF_CREATE_STATE(led_state_identify_entry,
						led_state_identify_run,
						NULL,
						NULL,
						NULL),
};
/* clang-format on */

static void led_tick(struct k_timer *timer)
{
	uint16_t ch;
	int err;

	ARG_UNUSED(timer);

	for (ch = 0; ch < ARRAY_SIZE(led_channel_ctx); ch++) {
		err = led_event_enqueue(ch, LED_EVENT_TICK);
		if (err != 0) {
			LOG_WRN("failed to enqueue LED tick event for channel %u (err %d)", ch,
				err);
		}
	}
}

int cannectivity_led_event(const struct device *dev, uint16_t ch, enum gs_usb_event event,
			   void *user_data)
{
	led_event_t led_event;
	struct led_ctx *lctx;
	int err;

	ARG_UNUSED(dev);
	ARG_UNUSED(user_data);

	if (ch >= ARRAY_SIZE(led_channel_ctx)) {
		LOG_ERR("event for non-existing channel %u", ch);
		return -EINVAL;
	}

	lctx = &led_channel_ctx[ch];

	switch (event) {
	case GS_USB_EVENT_CHANNEL_STARTED:
		LOG_DBG("channel %u started", ch);
		led_event = LED_EVENT_CHANNEL_STARTED;
		break;
	case GS_USB_EVENT_CHANNEL_STOPPED:
		LOG_DBG("channel %u stopped", ch);
		led_event = LED_EVENT_CHANNEL_STOPPED;
		break;
	case GS_USB_EVENT_CHANNEL_ERROR_ON:
		led_event = LED_EVENT_CHANNEL_ERROR_ON;
		break;
	case GS_USB_EVENT_CHANNEL_ERROR_OFF:
		led_event = LED_EVENT_CHANNEL_ERROR_OFF;
		break;
	case GS_USB_EVENT_CHANNEL_ACTIVITY_RX:
		__fallthrough;
	case GS_USB_EVENT_CHANNEL_ACTIVITY_TX:
		/* Low-pass filtering of RX/TX activity events is combined if no TX LED */
		led_event = LED_EVENT_CHANNEL_ACTIVITY_RX;
		int idx = LED_ACTIVITY_RX;

		if (event == GS_USB_EVENT_CHANNEL_ACTIVITY_TX) {
			led_event = LED_EVENT_CHANNEL_ACTIVITY_TX;

			if (LED_CTX_HAS_DUAL_ACTIVITY_LEDS(lctx)) {
				idx = LED_ACTIVITY_TX;
			}
		}

		if (!sys_timepoint_expired(lctx->activity[idx])) {
			goto skipped;
		}

		lctx->activity[idx] = sys_timepoint_calc(K_MSEC(LED_TICK_MS * LED_TICKS_ACTIVITY));
		break;
#if defined(CONFIG_USB_DEVICE_GS_USB_IDENTIFICATION) || defined(CONFIG_USBD_GS_USB_IDENTIFICATION)
	case GS_USB_EVENT_CHANNEL_IDENTIFY_ON:
		LOG_DBG("identify channel %u on", ch);
		led_event = LED_EVENT_CHANNEL_IDENTIFY_ON;
		break;
	case GS_USB_EVENT_CHANNEL_IDENTIFY_OFF:
		LOG_DBG("identify channel %u off", ch);
		led_event = LED_EVENT_CHANNEL_IDENTIFY_OFF;
		break;
#endif
	default:
		/* Unsupported event */
		goto skipped;
	}

	err = led_event_enqueue(ch, led_event);
	if (err != 0) {
		LOG_ERR("failed to enqueue LED event for channel %u (err %d)", ch, err);
	}

skipped:
	return 0;
}

static void led_event_triggered_work_handler(struct k_work *work)
{
	struct k_work_poll *pwork = CONTAINER_OF(work, struct k_work_poll, work);
	struct led_ctx *lctx = CONTAINER_OF(pwork, struct led_ctx, eventq_work);
	int err;

	err = k_msgq_get(&lctx->eventq, &lctx->event, K_NO_WAIT);
	if (err != 0) {
		LOG_ERR("failed to get event from queue (err %d)", err);
		goto resubmit;
	}

	err = smf_run_state(SMF_CTX(lctx));
	if (err != 0) {
		LOG_ERR("LED finite-state machine terminated (err %d)", err);
		goto resubmit;
	}

resubmit:
	err = k_work_poll_submit(&lctx->eventq_work, lctx->eventq_poll_events,
				 ARRAY_SIZE(lctx->eventq_poll_events), K_FOREVER);
	if (err != 0) {
		LOG_ERR("failed to re-submit event queue polling (err %d)", err);
	}
}

int cannectivity_led_init(void)
{
	struct led_ctx *lctx;
	uint16_t ch;
	int err;
	int i;

	for (ch = 0; ch < ARRAY_SIZE(led_channel_ctx); ch++) {
		lctx = &led_channel_ctx[ch];
		lctx->ch = ch;

		for (i = 0; i < ARRAY_SIZE(lctx->activity); i++) {
			lctx->activity[i] = sys_timepoint_calc(K_NO_WAIT);
		}

		if (LED_CTX_HAS_STATE_LED(lctx)) {
			if (!led_is_ready_dt(&lctx->state_led)) {
				LOG_ERR("state LED for channel %u not ready", ch);
				return -ENODEV;
			}
		}

		if (LED_CTX_HAS_ERROR_LED(lctx)) {
			if (!led_is_ready_dt(&lctx->error_led)) {
				LOG_ERR("error LED for channel %u not ready", ch);
				return -ENODEV;
			}
		}

		for (i = 0; i < ARRAY_SIZE(lctx->activity_led); i++) {
			if (lctx->activity_led[i].dev != NULL) {
				if (!led_is_ready_dt(&lctx->activity_led[i])) {
					LOG_ERR("activity LED %d for channel %u not ready", i, ch);
					return -ENODEV;
				}
			}
		}

		k_msgq_init(&lctx->eventq, lctx->eventq_buf, sizeof(led_event_t),
			    CONFIG_CANNECTIVITY_LED_EVENT_MSGQ_SIZE);

		k_poll_event_init(&lctx->eventq_poll_events[0], K_POLL_TYPE_MSGQ_DATA_AVAILABLE,
				  K_POLL_MODE_NOTIFY_ONLY, &lctx->eventq);

		k_work_poll_init(&lctx->eventq_work, led_event_triggered_work_handler);

		err = k_work_poll_submit(&lctx->eventq_work, lctx->eventq_poll_events, 1U,
					 K_FOREVER);
		if (err != 0) {
			LOG_ERR("failed to submit event queue polling (err %d)", err);
			return err;
		}

		smf_set_initial(SMF_CTX(lctx), &led_states[LED_STATE_NORMAL]);
	}

	k_timer_start(&led_tick_timer, K_MSEC(LED_TICK_MS), K_MSEC(LED_TICK_MS));

	return 0;
}
```

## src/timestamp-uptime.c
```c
/*
 * Copyright (c) 2025 Henrik Brix Andersen <henrik@brixandersen.dk>
 *
 * SPDX-License-Identifier: Apache-2.0
 */

#include <zephyr/kernel.h>
#include <zephyr/logging/log.h>

#include "cannectivity.h"

LOG_MODULE_REGISTER(timestamp, CONFIG_CANNECTIVITY_LOG_LEVEL);

int cannectivity_timestamp_get(const struct device *dev, uint32_t *timestamp, void *user_data)
{
	uint64_t cycles;

	ARG_UNUSED(dev);
	ARG_UNUSED(user_data);

	cycles = k_cycle_get_64();
	*timestamp = k_cyc_to_us_near32(cycles);

	return 0;
}

int cannectivity_timestamp_init(void)
{
	return 0;
}
```
